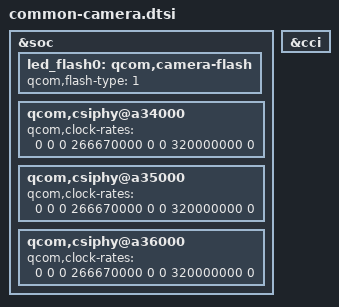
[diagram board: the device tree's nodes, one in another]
/*
 * Copyright (c) 2015 The Linux Foundation. All rights reserved.
 *
 * This program is free software; you can redistribute it and/or modify
 * it under the terms of the GNU General Public License version 2 and
 * only version 2 as published by the Free Software Foundation.
 *
 * This program is distributed in the hope that it will be useful,
 * but WITHOUT ANY WARRANTY; without even the implied warranty of
 * MERCHANTABILITY or FITNESS FOR A PARTICULAR PURPOSE.  See the
 * GNU General Public License for more details.
 */

&soc {
	led_flash0: qcom,camera-flash {
		qcom,flash-type = <1>;
	};

	qcom,csiphy@a34000 {
		qcom,clock-rates = <0 0 0 266670000 0 0 320000000 0>;
	};

	qcom,csiphy@a35000 {
		qcom,clock-rates = <0 0 0 266670000 0 0 320000000 0>;
	};

	qcom,csiphy@a36000 {
		qcom,clock-rates = <0 0 0 266670000 0 0 320000000 0>;
	};
};

&cci {
	/delete-node/ qcom,actuator@0;
	/delete-node/ qcom,actuator@1;
	/delete-node/ qcom,camera@0;
	/delete-node/ qcom,camera@1;
	/delete-node/ qcom,camera@2;
	/delete-node/ qcom,eeprom@0;
	/delete-node/ qcom,eeprom@1;
	/delete-node/ qcom,ois@0;
};
